AUTOSAR XML (schema 4-0-3)
package /AUTOSAR_WdgM/SwComponentTypes
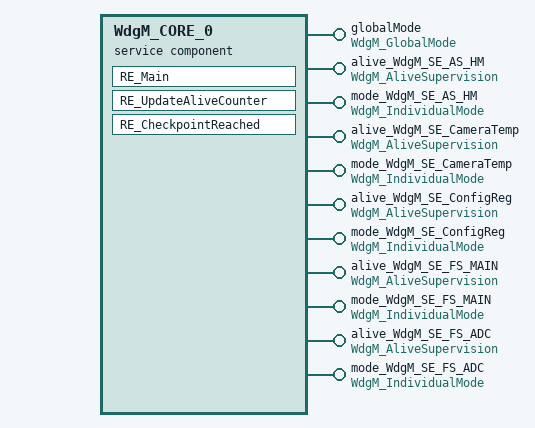
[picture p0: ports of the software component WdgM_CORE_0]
  service sw component type WdgM_CORE_0
    11 x provide port:
      globalMode: provided-interface=WdgM_GlobalMode
      alive_WdgM_SE_AS_HM: provided-com-specs=[{operation=UpdateAliveCounter, queue-length=1}, {operation=CheckpointReached, queue-length=1}], provided-interface=WdgM_AliveSupervision
      mode_WdgM_SE_AS_HM: provided-interface=WdgM_IndividualMode
      alive_WdgM_SE_CameraTemp: provided-com-specs=[{operation=UpdateAliveCounter, queue-length=1}, {operation=CheckpointReached, queue-length=1}], provided-interface=WdgM_AliveSupervision
      mode_WdgM_SE_CameraTemp: provided-interface=WdgM_IndividualMode
      alive_WdgM_SE_ConfigReg: provided-com-specs=[{operation=UpdateAliveCounter, queue-length=1}, {operation=CheckpointReached, queue-length=1}], provided-interface=WdgM_AliveSupervision
      mode_WdgM_SE_ConfigReg: provided-interface=WdgM_IndividualMode
      alive_WdgM_SE_FS_MAIN: provided-com-specs=[{operation=UpdateAliveCounter, queue-length=1}, {operation=CheckpointReached, queue-length=1}], provided-interface=WdgM_AliveSupervision
      mode_WdgM_SE_FS_MAIN: provided-interface=WdgM_IndividualMode
      alive_WdgM_SE_FS_ADC: provided-com-specs=[{operation=UpdateAliveCounter, queue-length=1}, {operation=CheckpointReached, queue-length=1}], provided-interface=WdgM_AliveSupervision
      mode_WdgM_SE_FS_ADC: provided-interface=WdgM_IndividualMode
    behavior SwcInternalBehavior_CORE_0: data-type-mapping=WdgMDataTypeMappingSet, handle-termination-and-restart=NO-SUPPORT
      10 x operation invoked event:
        EV_UpdateAliveCounter_SE_WdgM_SE_AS_HM: start-on-event=SwcInternalBehavior_CORE_0/RE_UpdateAliveCounter, operation=alive_WdgM_SE_AS_HM.UpdateAliveCounter
        EV_CheckpointReached_SE_WdgM_SE_AS_HM: start-on-event=SwcInternalBehavior_CORE_0/RE_CheckpointReached, operation=alive_WdgM_SE_AS_HM.CheckpointReached
        EV_UpdateAliveCounter_SE_WdgM_SE_CameraTemp: start-on-event=SwcInternalBehavior_CORE_0/RE_UpdateAliveCounter, operation=alive_WdgM_SE_CameraTemp.UpdateAliveCounter
        EV_CheckpointReached_SE_WdgM_SE_CameraTemp: start-on-event=SwcInternalBehavior_CORE_0/RE_CheckpointReached, operation=alive_WdgM_SE_CameraTemp.CheckpointReached
        EV_UpdateAliveCounter_SE_WdgM_SE_ConfigReg: start-on-event=SwcInternalBehavior_CORE_0/RE_UpdateAliveCounter, operation=alive_WdgM_SE_ConfigReg.UpdateAliveCounter
        EV_CheckpointReached_SE_WdgM_SE_ConfigReg: start-on-event=SwcInternalBehavior_CORE_0/RE_CheckpointReached, operation=alive_WdgM_SE_ConfigReg.CheckpointReached
        EV_UpdateAliveCounter_SE_WdgM_SE_FS_MAIN: start-on-event=SwcInternalBehavior_CORE_0/RE_UpdateAliveCounter, operation=alive_WdgM_SE_FS_MAIN.UpdateAliveCounter
        EV_CheckpointReached_SE_WdgM_SE_FS_MAIN: start-on-event=SwcInternalBehavior_CORE_0/RE_CheckpointReached, operation=alive_WdgM_SE_FS_MAIN.CheckpointReached
        EV_UpdateAliveCounter_SE_WdgM_SE_FS_ADC: start-on-event=SwcInternalBehavior_CORE_0/RE_UpdateAliveCounter, operation=alive_WdgM_SE_FS_ADC.UpdateAliveCounter
        EV_CheckpointReached_SE_WdgM_SE_FS_ADC: start-on-event=SwcInternalBehavior_CORE_0/RE_CheckpointReached, operation=alive_WdgM_SE_FS_ADC.CheckpointReached
      port-api-options:
        enable-take-address=true, indirect-api=false, port=globalMode
        {enable-take-address=false, indirect-api=false, port-defined-argument-value{value=PORTARG_SE_WdgM_SE_AS_HM:0, value-type=WdgM_SupervisedEntityIdType}, port=alive_WdgM_SE_AS_HM}
        enable-take-address=true, indirect-api=false, port=mode_WdgM_SE_AS_HM
        {enable-take-address=false, indirect-api=false, port-defined-argument-value{value=PORTARG_SE_WdgM_SE_CameraTemp:2, value-type=WdgM_SupervisedEntityIdType}, port=alive_WdgM_SE_CameraTemp}
        enable-take-address=true, indirect-api=false, port=mode_WdgM_SE_CameraTemp
        {enable-take-address=false, indirect-api=false, port-defined-argument-value{value=PORTARG_SE_WdgM_SE_ConfigReg:3, value-type=WdgM_SupervisedEntityIdType}, port=alive_WdgM_SE_ConfigReg}
        enable-take-address=true, indirect-api=false, port=mode_WdgM_SE_ConfigReg
        {enable-take-address=false, indirect-api=false, port-defined-argument-value{value=PORTARG_SE_WdgM_SE_FS_MAIN:4, value-type=WdgM_SupervisedEntityIdType}, port=alive_WdgM_SE_FS_MAIN}
        enable-take-address=true, indirect-api=false, port=mode_WdgM_SE_FS_MAIN
        {enable-take-address=false, indirect-api=false, port-defined-argument-value{value=PORTARG_SE_WdgM_SE_FS_ADC:5, value-type=WdgM_SupervisedEntityIdType}, port=alive_WdgM_SE_FS_ADC}
        enable-take-address=true, indirect-api=false, port=mode_WdgM_SE_FS_ADC
      runnable RE_Main: symbol=WdgM_MainFunction
        mode-access-points:
          globalMode.currentMode
          mode_WdgM_SE_AS_HM.currentMode
          mode_WdgM_SE_CameraTemp.currentMode
          mode_WdgM_SE_ConfigReg.currentMode
          mode_WdgM_SE_FS_MAIN.currentMode
          mode_WdgM_SE_FS_ADC.currentMode
        6 x mode switch point:
          MSP_globalMode: mode-group=globalMode.currentMode
          MSP_mode_WdgM_SE_AS_HM: mode-group=mode_WdgM_SE_AS_HM.currentMode
          MSP_mode_WdgM_SE_CameraTemp: mode-group=mode_WdgM_SE_CameraTemp.currentMode
          MSP_mode_WdgM_SE_ConfigReg: mode-group=mode_WdgM_SE_ConfigReg.currentMode
          MSP_mode_WdgM_SE_FS_MAIN: mode-group=mode_WdgM_SE_FS_MAIN.currentMode
          MSP_mode_WdgM_SE_FS_ADC: mode-group=mode_WdgM_SE_FS_ADC.currentMode
      runnable RE_UpdateAliveCounter: runnable-entity-argument=symbol=SEID, can-be-invoked-concurrently=true, symbol=WdgM_Rte_UpdateAliveCounter_CORE_0
      runnable RE_CheckpointReached: arguments=[symbol=SEID, symbol=CheckpointID], can-be-invoked-concurrently=true, symbol=WdgM_Rte_CheckpointReached_CORE_0
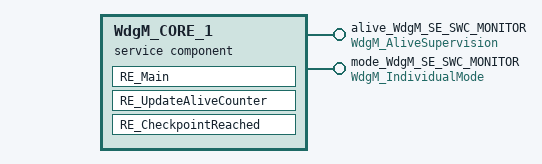
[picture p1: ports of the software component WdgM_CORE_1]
  service sw component type WdgM_CORE_1
    provide port alive_WdgM_SE_SWC_MONITOR: provided-com-specs=[{operation=UpdateAliveCounter, queue-length=1}, {operation=CheckpointReached, queue-length=1}], provided-interface=WdgM_AliveSupervision
    provide port mode_WdgM_SE_SWC_MONITOR: provided-interface=WdgM_IndividualMode
    behavior SwcInternalBehavior_CORE_1: data-type-mapping=WdgMDataTypeMappingSet, handle-termination-and-restart=NO-SUPPORT
      operation invoked event EV_UpdateAliveCounter_SE_WdgM_SE_SWC_MONITOR: start-on-event=SwcInternalBehavior_CORE_1/RE_UpdateAliveCounter, operation=alive_WdgM_SE_SWC_MONITOR.UpdateAliveCounter
      operation invoked event EV_CheckpointReached_SE_WdgM_SE_SWC_MONITOR: start-on-event=SwcInternalBehavior_CORE_1/RE_CheckpointReached, operation=alive_WdgM_SE_SWC_MONITOR.CheckpointReached
      port-api-options:
        {enable-take-address=false, indirect-api=false, port-defined-argument-value{value=PORTARG_SE_WdgM_SE_SWC_MONITOR:1, value-type=WdgM_SupervisedEntityIdType}, port=alive_WdgM_SE_SWC_MONITOR}
        enable-take-address=true, indirect-api=false, port=mode_WdgM_SE_SWC_MONITOR
      runnable RE_Main: mode-access-point=mode_WdgM_SE_SWC_MONITOR.currentMode, symbol=WdgM_1_CORE_1_MainFunction
        mode switch point MSP_mode_WdgM_SE_SWC_MONITOR: mode-group=mode_WdgM_SE_SWC_MONITOR.currentMode
      runnable RE_UpdateAliveCounter: runnable-entity-argument=symbol=SEID, can-be-invoked-concurrently=true, symbol=WdgM_Rte_UpdateAliveCounter_CORE_1
      runnable RE_CheckpointReached: arguments=[symbol=SEID, symbol=CheckpointID], can-be-invoked-concurrently=true, symbol=WdgM_Rte_CheckpointReached_CORE_1
package /EB_WdgM/SwcImplementations
  swc implementation SwcImplementation_CORE_0: programming-language=C, sw-version=6.2.3, vendor-id=1, behavior=SwcInternalBehavior_CORE_0
    code-descriptors:
      code WdgMCode: artifact-descriptors=autosar-engineering-object={short-label=EngObject, category=SWSRC}
    resource consumption Resources
      memory section CODE: sw-addrmethod=CODE
  swc implementation SwcImplementation_CORE_1: programming-language=C, sw-version=6.2.3, vendor-id=1, behavior=SwcInternalBehavior_CORE_1
    code-descriptors:
      code WdgMCode: artifact-descriptors=autosar-engineering-object={short-label=EngObject, category=SWSRC}
    resource consumption Resources
      memory section CODE: sw-addrmethod=CODE
